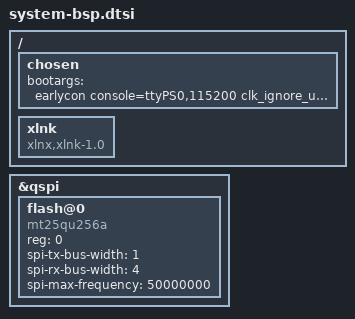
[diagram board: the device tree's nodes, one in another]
#include "include/dt-bindings/input/input.h"
#include "include/dt-bindings/interrupt-controller/irq.h"
#include "include/dt-bindings/gpio/gpio.h"
#include "include/dt-bindings/pinctrl/pinctrl-zynqmp.h"
#include "include/dt-bindings/phy/phy.h"

/ {
   chosen {
      bootargs = "earlycon console=ttyPS0,115200 clk_ignore_unused root=/dev/mmcblk0p2 rw rootwait cma=512M";
   };

   xlnk {
      compatible = "xlnx,xlnk-1.0";
   };

};

/* QSPI partitions are defined with petalinux-config and described in system.conf.dtsi */
&qspi { /* MIO 0-5 - U10 */
   flash@0 { /* ISSI IS25WP256E */
      compatible = "mt25qu256a", "jedec,spi-nor"; /* 32MB */
      #address-cells = <1>;
      #size-cells = <1>;
      reg = <0>;
      spi-tx-bus-width = <1>;
      spi-rx-bus-width = <4>;
      spi-max-frequency = <50000000>; /* 50MHz */
   };

};



